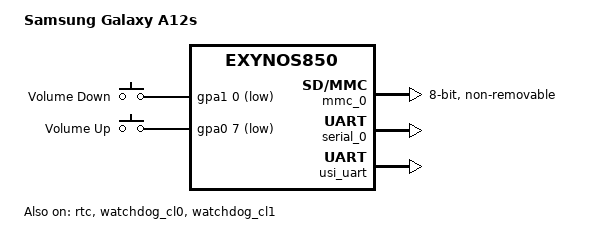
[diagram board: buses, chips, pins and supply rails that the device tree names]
// SPDX-License-Identifier: GPL-2.0
/*
 * Samsung Galaxy A12s (SM-A127F) device tree source
 *
 * SoC: Samsung Exynos 850 (also known as Exynos 3830)
 */

/dts-v1/;

#include "exynos850.dtsi"
#include <dt-bindings/gpio/gpio.h>
#include <dt-bindings/input/input.h>

/ {
	model = "Samsung Galaxy A12s";
	compatible = "samsung,a12s", "samsung,exynos850";
	chassis-type = "handset";

	aliases {
		mmc0 = &mmc_0;
		serial0 = &serial_0;
	};

	chosen {
		stdout-path = &serial_0;
	};

	memory@80000000 {
		device_type = "memory";
		reg = <0x0 0x80000000 0x40000000>;
	};

	rtcclk: clock-rtcclk {
		compatible = "fixed-clock";
		clock-output-names = "rtcclk";
		#clock-cells = <0>;
		clock-frequency = <32768>;
	};

	gpio-keys {
		compatible = "gpio-keys";
		pinctrl-names = "default";
		pinctrl-0 = <&key_voldown_pins &key_volup_pins>;

		volume-down-key {
			label = "Volume Down";
			linux,code = <KEY_VOLUMEDOWN>;
			gpios = <&gpa1 0 GPIO_ACTIVE_LOW>;
		};

		volume-up-key {
			label = "Volume Up";
			linux,code = <KEY_VOLUMEUP>;
			gpios = <&gpa0 7 GPIO_ACTIVE_LOW>;
		};
	};
};

&cmu_hsi {
	clocks = <&oscclk>, <&rtcclk>,
		 <&cmu_top CLK_DOUT_HSI_BUS>,
		 <&cmu_top CLK_DOUT_HSI_MMC_CARD>,
		 <&cmu_top CLK_DOUT_HSI_USB20DRD>;
	clock-names = "oscclk", "rtcclk", "dout_hsi_bus",
		      "dout_hsi_mmc_card", "dout_hsi_usb20drd";
};

&mmc_0 {
	status = "okay";
	mmc-hs200-1_8v;
	mmc-hs400-1_8v;
	cap-mmc-highspeed;
	non-removable;
	bus-width = <8>;
	pinctrl-names = "default";
	pinctrl-0 = <&sd0_clk_pins &sd0_cmd_pins &sd0_rdqs_pins
		     &sd0_bus1_pins &sd0_bus4_pins &sd0_bus8_pins>;
};

&oscclk {
	clock-frequency = <26000000>;
};

&pinctrl_alive {
	key_voldown_pins: key-voldown-pins {
		samsung,pins = "gpa1-0";
		samsung,pin-function = <EXYNOS_PIN_FUNC_EINT>;
		samsung,pin-pud = <EXYNOS_PIN_PULL_NONE>;
		samsung,pin-drv = <EXYNOS5420_PIN_DRV_LV1>;
	};

	key_volup_pins: key-volup-pins {
		samsung,pins = "gpa0-7";
		samsung,pin-function = <EXYNOS_PIN_FUNC_EINT>;
		samsung,pin-pud = <EXYNOS_PIN_PULL_NONE>;
		samsung,pin-drv = <EXYNOS5420_PIN_DRV_LV1>;
	};
};

&rtc {
	status = "okay";
	clocks = <&cmu_apm CLK_GOUT_RTC_PCLK>, <&rtcclk>;
	clock-names = "rtc", "rtc_src";
};

&serial_0 {
	status = "okay";
	pinctrl-names = "default";
	pinctrl-0 = <&uart1_pins>;
};

&usi_uart {
	samsung,clkreq-on;
	status = "okay";
};

&watchdog_cl0 {
	status = "okay";
};

&watchdog_cl1 {
	status = "okay";
};
